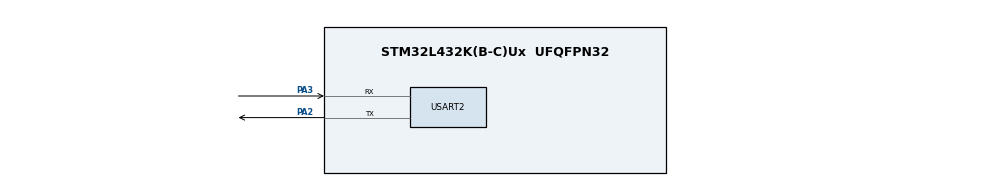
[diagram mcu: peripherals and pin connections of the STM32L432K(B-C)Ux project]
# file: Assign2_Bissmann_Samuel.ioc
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FREERTOS.CountingSemaphores01=myCountingSem01,2,Dynamic,NULL
FREERTOS.Tasks01=ConsumerTask,24,128,ConsumerTask_Entry,Default,NULL,Dynamic,NULL,NULL
FREERTOS.configGENERATE_RUN_TIME_STATS=1
FREERTOS.configTOTAL_HEAP_SIZE=30000
FREERTOS.configUSE_NEWLIB_REENTRANT=1
Mcu.Family=STM32L4
Mcu.Name=STM32L432K(B-C)Ux
Mcu.Package=UFQFPN32
NVIC.PriorityGroup=NVIC_PRIORITYGROUP_4
PA2.Mode=Asynchronous
PA2.Signal=USART2_TX
PA3.Mode=Asynchronous
PA3.Signal=USART2_RX
ProjectManager.HeapSize=0x200
ProjectManager.StackSize=0x400
ProjectManager.TargetToolchain=STM32CubeIDE
RCC.HSE_VALUE=8000000
RCC.HSI48_VALUE=48000000
RCC.HSI_VALUE=16000000
RCC.LSE_VALUE=32768
RCC.MSI_VALUE=4000000
RCC.VCOOutputFreq_Value=32000000
USART2.VirtualMode-Asynchronous=VM_ASYNC
VP_FREERTOS_VS_CMSIS_V2.Mode=CMSIS_V2
board=custom

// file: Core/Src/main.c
/* USER CODE BEGIN Header */
/**
  ******************************************************************************
  * @file           : main.c
  * @brief          : Main program body
  ******************************************************************************
  * @attention
  *
  * Copyright (c) 2024 STMicroelectronics.
  * All rights reserved.
  *
  * This software is licensed under terms that can be found in the LICENSE file
  * in the root directory of this software component.
  * If no LICENSE file comes with this software, it is provided AS-IS.
  *
  ******************************************************************************
  */
/* USER CODE END Header */
#include "main.h"
#include "cmsis_os.h"

/* USER CODE BEGIN Includes */
#include "semphr.h"
#include <stdbool.h>
#include <stdio.h>
/* USER CODE END Includes */

/* USER CODE BEGIN PTD */

#define NUM_PRODS 7
#define RING_BUFFER_SIZE 10
#define PRODUCER_TIME 1000
#define CONSUMER_TIME 90

typedef struct{
	int data;
	osThreadId_t producer_task;
}
rb_elem;

typedef struct{
	rb_elem buffer[RING_BUFFER_SIZE];
	SemaphoreHandle_t mutex;
	SemaphoreHandle_t items;

	int head;
	int tail;
}ring_buffer;

/* USER CODE END PTD */

UART_HandleTypeDef huart2;

/* Definitions for ConsumerTask */
osThreadId_t ConsumerTaskHandle;
const osThreadAttr_t ConsumerTask_attributes = {
  .name = "ConsumerTask",
  .stack_size = 128 * 4,
  .priority = (osPriority_t) osPriorityNormal,
};
/* Definitions for myCountingSem01 */
osSemaphoreId_t myCountingSem01Handle;
const osSemaphoreAttr_t myCountingSem01_attributes = {
  .name = "myCountingSem01"
};
/* USER CODE BEGIN PV */
osThreadId_t ProducerTaskHandle;
const osThreadAttr_t ProducerTask_attributes = {
  .stack_size = 128 * 4,
  .priority = (osPriority_t) osPriorityNormal,
};

static ring_buffer rb;

/* USER CODE END PV */

void SystemClock_Config(void);
static void MX_GPIO_Init(void);
static void MX_USART2_UART_Init(void);
void ConsumerTask_Entry(void *argument);
void ProducerTask_Entry(void *argument);

/* USER CODE BEGIN PFP */
bool Ringbuffer_Put(rb_elem elem);
bool Ringbuffer_Get(rb_elem *elem);

/* USER CODE END PFP */

/* USER CODE BEGIN 0 */

int __io_putchar(int ch)
{
	int ret;
	while ((ret=HAL_UART_GetState(&huart2)) != HAL_UART_STATE_READY)
		;

	if (ch == '\n')
	{
		static uint8_t buf[2] = { '\r', '\n' };
		HAL_UART_Transmit(&huart2, buf, sizeof(buf), 1000);
	}
	else
	{
		static char buf;
		buf = ch;
		HAL_UART_Transmit(&huart2, (uint8_t *)&buf, 1, 1000);
	}
	return ch;
}

bool Ringbuffer_Put(rb_elem elem)
{
    if (xSemaphoreTake(rb.mutex, portMAX_DELAY) == pdTRUE) {
        // Check if there's space in the buffer
        if (uxSemaphoreGetCount(rb.items) < RING_BUFFER_SIZE) {

        	//Update head
            rb.buffer[rb.head] = elem;
            rb.head++;
            rb.head=rb.head%10;

            // Increment the count of items in the buffer
            xSemaphoreGive(rb.items);

            xSemaphoreGive(rb.mutex);
            return true;
        }
        else {
            printf("Buffer Full!");
            xSemaphoreGive(rb.mutex);
        }
    }
    return false; // Return false if mutex couldn't be acquired
}

bool Ringbuffer_Get(rb_elem *elem) {
    if (xSemaphoreTake(rb.mutex, portMAX_DELAY) == pdTRUE) {
        // Check if there are any items in the buffer
        if (uxSemaphoreGetCount(rb.items) > 0) {

            *elem = rb.buffer[rb.tail];
            rb.tail++;
            rb.tail=rb.tail%10;

            xSemaphoreTake(rb.items, portMAX_DELAY);
            xSemaphoreGive(rb.mutex);
            return true;
        }
        else {
            // Buffer is empty
            xSemaphoreGive(rb.mutex);
            return false;
        }
    }
    return false;
}

/* USER CODE END 0 */

int main(void)
{

  /* MCU Configuration--------------------------------------------------------*/

  /* Reset of all peripherals, Initializes the Flash interface and the Systick. */
  HAL_Init();

  /* Configure the system clock */
  SystemClock_Config();

  /* Initialize all configured peripherals */
  MX_GPIO_Init();
  MX_USART2_UART_Init();

  /* Init scheduler */
  osKernelInitialize();

  /* USER CODE BEGIN RTOS_MUTEX */
rb.mutex=xSemaphoreCreateMutex();
rb.items=xSemaphoreCreateCounting(RING_BUFFER_SIZE,0);

  /* add mutexes, ... */
  /* USER CODE END RTOS_MUTEX */

  /* Create the semaphores(s) */
  /* creation of myCountingSem01 */
  myCountingSem01Handle = osSemaphoreNew(2, 2, &myCountingSem01_attributes);

  /* Create the thread(s) */
  /* creation of ConsumerTask */
  ConsumerTaskHandle = osThreadNew(ConsumerTask_Entry, NULL, &ConsumerTask_attributes);

  /* USER CODE BEGIN RTOS_THREADS */

  //Creation of threads
  for(int i=1;i<=NUM_PRODS;i++)
  {
	  osThreadId_t ProducerCreated=osThreadNew(ProducerTask_Entry, (void*)i, &ProducerTask_attributes);

	 if(ProducerCreated==NULL)
	 {
		 printf("creation of: %d failed \n",i);

	 }
	 else
	 {
	printf("created: %d StackSize: %d\n",i,(int)osThreadGetStackSpace(ProducerCreated));

	 }

  }

  /* add threads, ... */
  /* USER CODE END RTOS_THREADS */

  /* Start scheduler */
  osKernelStart();

  /* We should never get here as control is now taken by the scheduler */
  /* Infinite loop */
  while (1)
  {

  }
}

void SystemClock_Config(void)
{
  RCC_OscInitTypeDef RCC_OscInitStruct = {0};
  RCC_ClkInitTypeDef RCC_ClkInitStruct = {0};

  /** Configure the main internal regulator output voltage
  */
  if (HAL_PWREx_ControlVoltageScaling(PWR_REGULATOR_VOLTAGE_SCALE1) != HAL_OK)
  {
    Error_Handler();
  }

  /** Initializes the RCC Oscillators according to the specified parameters
  * in the RCC_OscInitTypeDef structure.
  */
  RCC_OscInitStruct.OscillatorType = RCC_OSCILLATORTYPE_MSI;
  RCC_OscInitStruct.MSIState = RCC_MSI_ON;
  RCC_OscInitStruct.MSICalibrationValue = 0;
  RCC_OscInitStruct.MSIClockRange = RCC_MSIRANGE_6;
  RCC_OscInitStruct.PLL.PLLState = RCC_PLL_NONE;
  if (HAL_RCC_OscConfig(&RCC_OscInitStruct) != HAL_OK)
  {
    Error_Handler();
  }

  /** Initializes the CPU, AHB and APB buses clocks
  */
  RCC_ClkInitStruct.ClockType = RCC_CLOCKTYPE_HCLK|RCC_CLOCKTYPE_SYSCLK
                              |RCC_CLOCKTYPE_PCLK1|RCC_CLOCKTYPE_PCLK2;
  RCC_ClkInitStruct.SYSCLKSource = RCC_SYSCLKSOURCE_MSI;
  RCC_ClkInitStruct.AHBCLKDivider = RCC_SYSCLK_DIV1;
  RCC_ClkInitStruct.APB1CLKDivider = RCC_HCLK_DIV1;
  RCC_ClkInitStruct.APB2CLKDivider = RCC_HCLK_DIV1;

  if (HAL_RCC_ClockConfig(&RCC_ClkInitStruct, FLASH_LATENCY_0) != HAL_OK)
  {
    Error_Handler();
  }
}

static void MX_USART2_UART_Init(void)
{

  huart2.Instance = USART2;
  huart2.Init.BaudRate = 115200;
  huart2.Init.WordLength = UART_WORDLENGTH_8B;
  huart2.Init.StopBits = UART_STOPBITS_1;
  huart2.Init.Parity = UART_PARITY_NONE;
  huart2.Init.Mode = UART_MODE_TX_RX;
  huart2.Init.HwFlowCtl = UART_HWCONTROL_NONE;
  huart2.Init.OverSampling = UART_OVERSAMPLING_16;
  huart2.Init.OneBitSampling = UART_ONE_BIT_SAMPLE_DISABLE;
  huart2.AdvancedInit.AdvFeatureInit = UART_ADVFEATURE_NO_INIT;
  if (HAL_UART_Init(&huart2) != HAL_OK)
  {
    Error_Handler();
  }

}

static void MX_GPIO_Init(void)
{

  /* GPIO Ports Clock Enable */
  __HAL_RCC_GPIOA_CLK_ENABLE();

}

/* USER CODE BEGIN 4 */

/**
* @brief Function implementing the ProducerTask thread.
* Puts Data element with Producer ID in the Buffer.
* Runs cyclically in Producer_Time
* @param argument: Id of the producing task
* @retval None
*/
void ProducerTask_Entry(void *argument) {
    // Get the ID of the current thread
    osThreadId_t producerId = osThreadGetId();

    rb_elem data;
    data.data = (int)argument;
    data.producer_task = producerId;

    while (1) {
        // Add data to ring buffer

    	if(Ringbuffer_Put(data))
    	{
    		printf("produced			\n");
    	}
    	else
    	{

    		printf("Buffer Full			\n");
    	}

        osDelay(PRODUCER_TIME);

    }
}

/* USER CODE END 4 */

/* USER CODE BEGIN Header_ConsumerTask_Entry */
/**
* @brief Function implementing the ConsumerTask thread.
* Prints the data element task id, prod-Tasks run cyclically in CONSUMER_TIME interval
* @param argument: Not used
* @retval None
*/
/* USER CODE END Header_ConsumerTask_Entry */
void ConsumerTask_Entry(void *argument)
{
  /* USER CODE BEGIN 5 */
	while (1) {
	        rb_elem data;

	        if (Ringbuffer_Get(&data)) {

	        	 printf("Received Data from Task-ID: %d, Thread-No: %p\n", data.data,data.producer_task);
	        }
	        else
	        {

	        	printf("		Im empty \n");
	        }
	        osDelay(CONSUMER_TIME);
	    }
  /* USER CODE END 5 */
}

void Error_Handler(void)
{
  __disable_irq();
  while (1)
  {
  }
}
